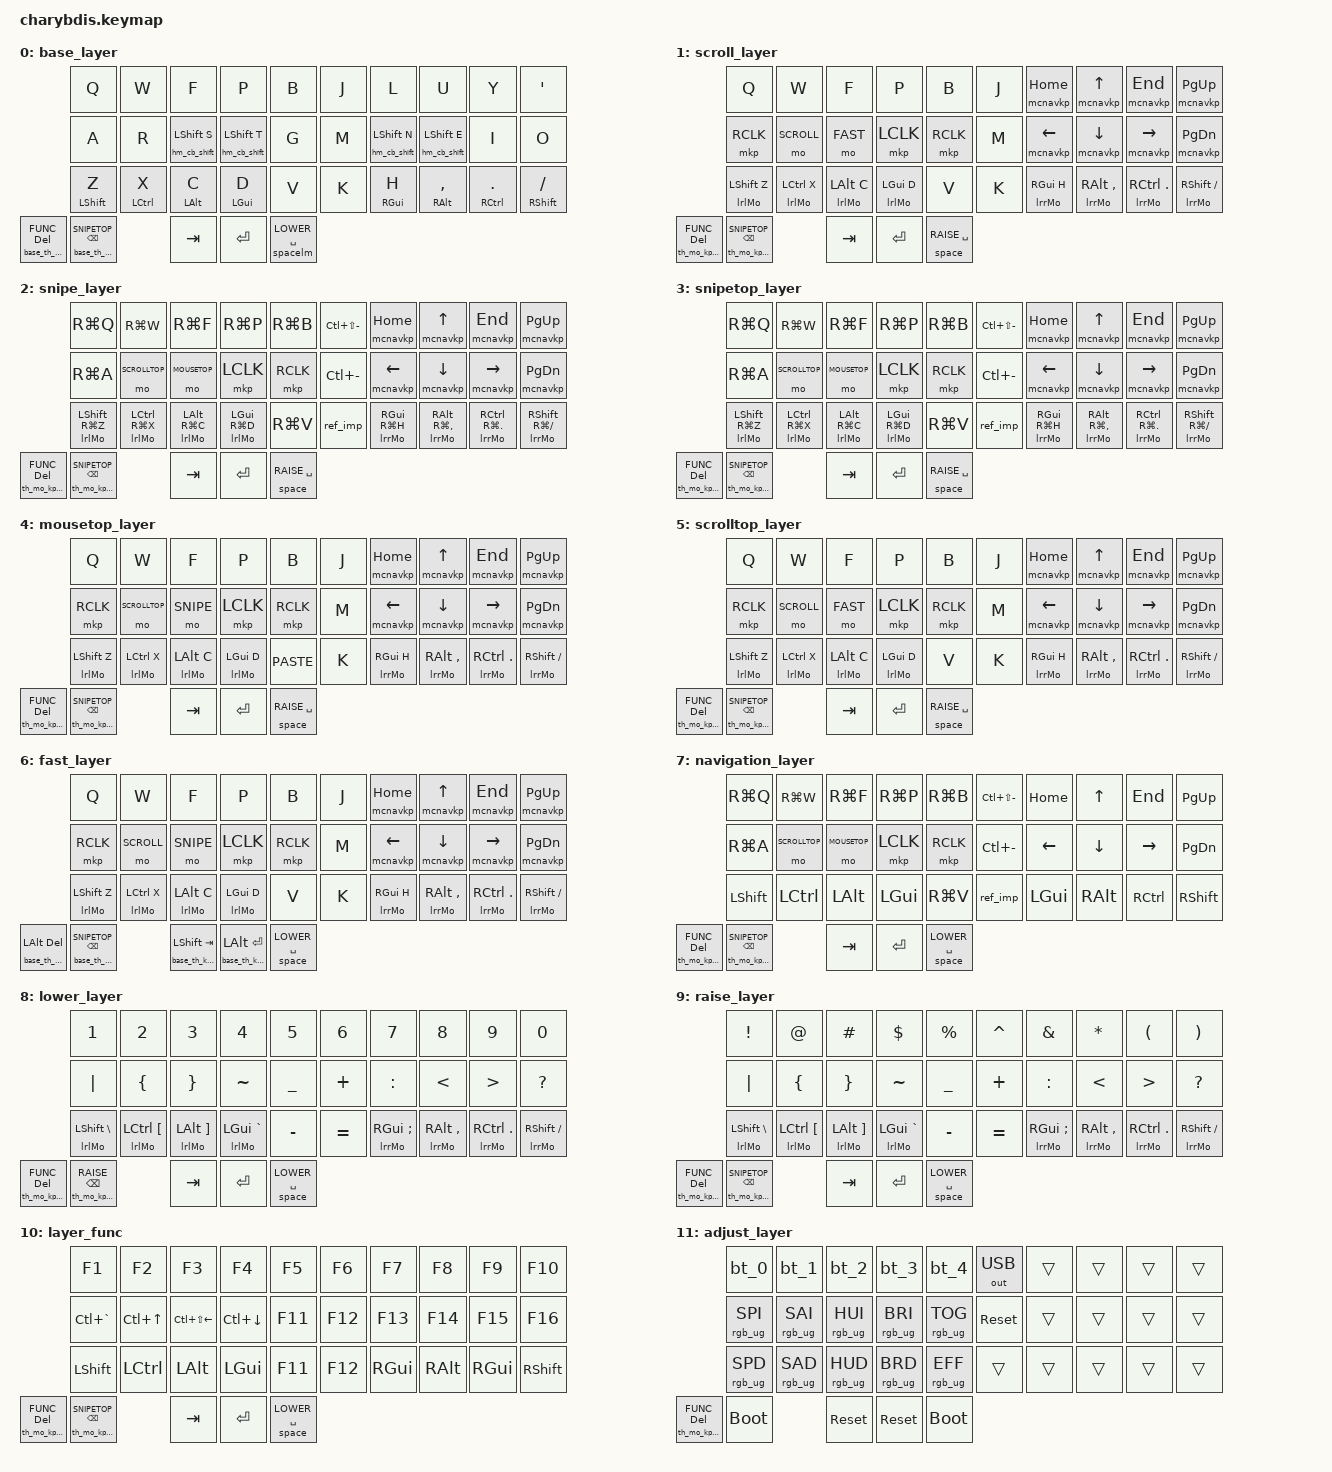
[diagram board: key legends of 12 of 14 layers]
/*
cd /Users/haroldhernandez/Charybdis/zmk-config-charybdis_nano

source ~/zephyrproject/.venv/bin/activate


//To install local zmk
# Tell west the config directory included in this repo
west init -l config
west update                # fetch Zephyr, ZMK, HALs
west zephyr-export         # sets Zephyr CMake package files in venv


west build -p \
  -s zmk/app -b nice_nano_v2 -d build/right \
  -S zmk-usb-logging \
  -S studio-rpc-usb-uart \
  -- \
  -DZMK_CONFIG="${PWD}/config" \
  -DOVERLAY_CONFIG=${PWD}/config/debug.conf \
  -DSHIELD=charybdis_right



west build -p \
  -s zmk/app -b nice_nano_v2 -d build/left \
  -S zmk-usb-logging \
  -- \
  -DZMK_CONFIG="${PWD}/config" \
  -DOVERLAY_CONFIG=${PWD}/config/debug.conf \
  -DSHIELD=charybdis_left

#To check the numbers:

   ls /dev/tty.usbmodem*   # data-terminal devices
   ls /dev/cu.usbmodem*    # call-up devices (identical, no HW flow-ctrl)

#and run to actuvate debug 
   sudo tio /dev/tty.usbmodem1101
   
-------------------------------------------------

west build -p \
  -s zmk/app -b nice_nano_v2 -d build/right \
  -- \
  -DZMK_CONFIG="${PWD}/config" \
  -DOVERLAY_CONFIG=${PWD}/config/debug.conf \
  -DSHIELD=charybdis_right



west build -p \
  -s zmk/app -b nice_nano_v2 -d build/left \
  -- \
  -DZMK_CONFIG="${PWD}/config" \
  -DOVERLAY_CONFIG=${PWD}/config/debug.conf \
  -DSHIELD=charybdis_left



  1. First boot — plug in USB, open a serial terminal:                                                           
  ls /dev/tty.usbmodem*                                                                                        
  screen /dev/tty.usbmodem* 115200                                                                               
  1. Confirm trackball works, note log output (should see PMW3610 initialized)                                   
  2. Power cycle — unplug USB, unplug battery, wait 5 seconds, plug battery back in, then plug USB back in       
  3. Second boot — open serial terminal again (the device name may change), check if PMW3610 initialized appears 
  or if you see errors/retries 


//ONLY RIGHT
west build -p \
  -s zmk/app -b nice_nano_v2 -d build/right \
  -S zmk-usb-logging \
  -- \
  -DZMK_CONFIG="${PWD}/config" \
  -DOVERLAY_CONFIG=${PWD}/config/debug.conf \
  -DSHIELD=charybdis_right


  west build -p \
  -s zmk/app -b nice_nano_v2 -d build/right \
  -S zmk-usb-logging \
  -- \
  -DZMK_CONFIG="${PWD}/config" \
  -DSHIELD=charybdis_right



  
west build -p \
  -s zmk/app -b nice_nano_v2 -d build/left \
  -- \
  -DZMK_CONFIG="${PWD}/config" \
  -DSHIELD=charybdis_left

west build -p \
  -s zmk/app -b nice_nano_v2 -d build/right \
  -- \
  -DZMK_CONFIG="${PWD}/config" \
  -DSHIELD=charybdis_right

*/

// ZMK_POINTING_DEFAULT_MOVE_VAL and ZMK_POINTING_DEFAULT_SCRL_VAL
// are defined in mouse.dtsi (included below)

/* On demand includes */

#include <behaviors/mouse_keys.dtsi>
#include <dt-bindings/zmk/mouse.h>
#include <behaviors.dtsi>
#include <behaviors/rgb_underglow.dtsi>
#include <dt-bindings/zmk/bt.h>
#include <dt-bindings/zmk/keys.h>
#include <dt-bindings/zmk/rgb.h>
#include <dt-bindings/zmk/outputs.h>
#include <dt-bindings/zmk/pointing.h>
//#include <input/processors.dtsi>


//     0  1  2  3  4         5  6  7  8  9
//    10 11 12 13 14        15 16 17 18 19
//    20 21 22 23 24        25 26 27 28 29 
//    30 31 32 33 34 35  36 37          38

//     0  1  2  3  4     5  6  7  8  9
//    10 11 12 13 14    15 16 17 18 19
//20  21 22 23 24 25    26 27 28 29 30  31
//        32 33 34         35 36 37


&lt {
    tapping-term-ms = <240>;
    flavor = "balanced";
    quick-tap-ms = <150>;
};

&mt {
    tapping-term-ms = <200>;
    flavor = "tap-preferred";
    quick-tap-ms = <150>;
};

&sl {
    release-after-ms = <4000>;
};

&caps_word { continue-list = <UNDERSCORE MINUS BACKSPACE>; };
#include "mouse.dtsi"

/ {
    chosen { zmk,matrix_transform = &five_column_transform; };
};

/ {

    #include "macros/macros_general.dtsi"
    #include "behaviors/behaviors_general.dtsi"
    #include "combos/combos_general.dtsi"

    keymap {
        compatible = "zmk,keymap";
        base_layer {
            bindings = <
                               &kp Q                &kp W               &kp F                      &kp P                     &kp B                     &kp J    &kp L                     &kp U                      &kp Y                &kp SQT
                               &kp A                &kp R               &hm_cb_shift LSHFT S       &hm_cb_shift LSHFT T      &kp G                     &kp M    &hm_cb_shift LSHFT N      &hm_cb_shift LSHFT E       &kp I                &kp O
                               &hml_hr LSHFT Z      &hml_hr LCTRL X     &hml_hr LALT C             &hml_hr LGUI D            &kp V                     &kp K    &hmr_hr RGUI H            &hmr_hr RALT COMMA         &hmr_hr RCTRL DOT    &hmr_hr RSHFT SLASH        
 &base_th_mo_kp_hp FUNC DEL  &base_th_mo_kp_hp SNIPETOP BACKSPACE  &kp TAB                 &kp ENTER  &spacelm LOWER SPACE  
            >;
        };

         scroll_layer {
            bindings = <
&kp Q                      &kp W                    &kp F                &kp P                 &kp B                                 &kp J           &mcnavkp HOME              &mcnavkp UP                    &mcnavkp END                    &mcnavkp PG_UP
&mkp RCLK                  &mo SCROLL               &mo FAST             &mkp LCLK             &mkp RCLK                             &kp M           &mcnavkp LEFT              &mcnavkp DOWN                  &mcnavkp RIGHT                  &mcnavkp PG_DN
&lrlMo LSHFT Z             &lrlMo LCTRL X           &lrlMo LALT C        &lrlMo LGUI D         &kp V                                 &kp K           &lrrMo RGUI H              &lrrMo RALT COMMA              &lrrMo RCTRL DOT                &lrrMo RSHFT SLASH 
//&kp DEL  &kp BACKSPACE  &kp TAB                  &kp ENTER   &kp SPACE   
  &th_mo_kp_hp FUNC DEL  &th_mo_kp_hp SNIPETOP BACKSPACE  &kp TAB                  &kp ENTER   &space RAISE SPACE   
            >;
        };

        snipe_layer {
            bindings = <
&kp RG(Q)                  &kp RG(W)                   &kp RG(F)             &kp RG(P)             &kp RG(B)                             &kp LC(LS(MINUS))           &mcnavkp HOME              &mcnavkp UP                    &mcnavkp END                    &mcnavkp PG_UP
&kp RG(A)                  &mo SCROLLTOP               &mo MOUSETOP          &mkp LCLK             &mkp RCLK                             &kp LC(MINUS)               &mcnavkp LEFT              &mcnavkp DOWN                  &mcnavkp RIGHT                  &mcnavkp PG_DN
&lrlMo LSHFT RG(Z)        &lrlMo LCTRL RG(X)         &lrlMo LALT RG(C)    &lrlMo LGUI RG(D)    &kp RG(V)                             &ref_imp                    &lrrMo RGUI RG(H)          &lrrMo RALT RG(COMMA)          &lrrMo RCTRL RG(DOT)            &lrrMo RSHFT RG(SLASH) 
//&kp DEL  &kp BACKSPACE  &kp TAB                  &kp ENTER   &kp SPACE   
  &th_mo_kp_hp FUNC DEL  &th_mo_kp_hp SNIPETOP BACKSPACE  &kp TAB                   &kp ENTER   &space RAISE SPACE   
            >;
        };

        snipetop_layer {
            bindings = <
&kp RG(Q)                  &kp RG(W)                   &kp RG(F)             &kp RG(P)             &kp RG(B)                             &kp LC(LS(MINUS))           &mcnavkp HOME              &mcnavkp UP                    &mcnavkp END                    &mcnavkp PG_UP
&kp RG(A)                  &mo SCROLLTOP               &mo MOUSETOP          &mkp LCLK             &mkp RCLK                             &kp LC(MINUS)               &mcnavkp LEFT              &mcnavkp DOWN                  &mcnavkp RIGHT                  &mcnavkp PG_DN
&lrlMo LSHFT RG(Z)        &lrlMo LCTRL RG(X)         &lrlMo LALT RG(C)    &lrlMo LGUI RG(D)    &kp RG(V)                             &ref_imp                    &lrrMo RGUI RG(H)          &lrrMo RALT RG(COMMA)          &lrrMo RCTRL RG(DOT)            &lrrMo RSHFT RG(SLASH) 
//&kp DEL  &kp BACKSPACE  &kp TAB                  &kp ENTER   &kp SPACE   
  &th_mo_kp_hp FUNC DEL  &th_mo_kp_hp SNIPETOP BACKSPACE  &kp TAB                   &kp ENTER   &space RAISE SPACE   
            >;
        };

        mousetop_layer {
            bindings = <
&kp Q                      &kp W                    &kp F                 &kp P                 &kp B                                   &kp J           &mcnavkp HOME              &mcnavkp UP                    &mcnavkp END                    &mcnavkp PG_UP
&mkp RCLK                  &mo SCROLLTOP            &mo SNIPE             &mkp LCLK             &mkp RCLK                               &kp M           &mcnavkp LEFT              &mcnavkp DOWN                  &mcnavkp RIGHT                  &mcnavkp PG_DN
&lrlMo LSHFT Z            &lrlMo LCTRL X          &lrlMo LALT C        &lrlMo LGUI D        &kp K_PASTE                             &kp K           &lrrMo RGUI H              &lrrMo RALT COMMA              &lrrMo RCTRL DOT                &lrrMo RSHFT SLASH 
//&kp DEL  &kp BACKSPACE  &kp TAB                  &kp ENTER   &kp SPACE   
 &th_mo_kp_hp FUNC DEL  &th_mo_kp_hp SNIPETOP BACKSPACE  &kp TAB                         &kp ENTER   &space RAISE SPACE   
            >;
        };

        scrolltop_layer {
            bindings = <
&kp Q                      &kp W                    &kp F                &kp P                 &kp B                                 &kp J               &mcnavkp HOME              &mcnavkp UP                    &mcnavkp END                    &mcnavkp PG_UP
&mkp RCLK                  &mo SCROLL               &mo FAST             &mkp LCLK             &mkp RCLK                             &kp M               &mcnavkp LEFT              &mcnavkp DOWN                  &mcnavkp RIGHT                  &mcnavkp PG_DN
&lrlMo LSHFT Z            &lrlMo LCTRL X          &lrlMo LALT C       &lrlMo LGUI D        &kp V                                 &kp K               &lrrMo RGUI H              &lrrMo RALT COMMA              &lrrMo RCTRL DOT                &lrrMo RSHFT SLASH 
//&kp DEL  &kp BACKSPACE  &kp TAB                  &kp ENTER   &kp SPACE   
 &th_mo_kp_hp FUNC DEL  &th_mo_kp_hp SNIPETOP BACKSPACE  &kp TAB                   &kp ENTER   &space RAISE SPACE   
            >;
        };

    fast_layer {
        bindings = <
&kp Q                      &kp W                    &kp F                  &kp P                  &kp B                                 &kp J               &mcnavkp HOME              &mcnavkp UP                    &mcnavkp END                    &mcnavkp PG_UP
&mkp RCLK                  &mo SCROLL               &mo SNIPE              &mkp LCLK              &mkp RCLK                             &kp M               &mcnavkp LEFT              &mcnavkp DOWN                  &mcnavkp RIGHT                  &mcnavkp PG_DN
&lrlMo LSHFT Z             &lrlMo LCTRL X           &lrlMo LALT C          &lrlMo LGUI D          &kp V                                 &kp K               &lrrMo RGUI H              &lrrMo RALT COMMA              &lrrMo RCTRL DOT                &lrrMo RSHFT SLASH 
 &base_th_mo_kp_hp LALT DEL  &base_th_mo_kp_hp SNIPETOP BACKSPACE  &base_th_kp_kp_hp LSHFT TAB                    &base_th_kp_kp_hp LALT ENTER  &space LOWER SPACE  
        >;
    };
    
    navigation_layer {
            bindings = <
&kp RG(Q)                  &kp RG(W)                   &kp RG(F)             &kp RG(P)             &kp RG(B)                             &kp LC(LS(MINUS))           &kp HOME                   &kp UP                         &kp END                         &kp PG_UP
&kp RG(A)                  &mo SCROLLTOP               &mo MOUSETOP          &mkp LCLK             &mkp RCLK                             &kp LC(MINUS)               &kp LEFT                   &kp DOWN                       &kp RIGHT                       &kp PG_DN
&kp LSHFT                  &kp LCTRL                   &kp LALT              &kp LGUI              &kp RG(V)                             &ref_imp                    &kp LGUI                   &kp RALT                       &kp RCTRL                       &kp RSHFT  
//&kp DEL  &kp BACKSPACE  &kp TAB                  &kp ENTER   &kp SPACE   
  &th_mo_kp_hp FUNC DEL  &th_mo_kp_hp SNIPETOP BACKSPACE  &kp TAB                   &kp ENTER   &space LOWER SPACE   
            >;
        };

        lower_layer {
            bindings = <
                  &kp N1                         &kp N2                        &kp N3                        &kp N4              &kp N5                                    &kp N6             &kp N7                    &kp N8                   &kp N9                 &kp N0
                  &kp PIPE                       &kp LBRC                      &kp RBRC                      &kp TILDE           &kp UNDER                                 &kp PLUS           &kp COLON                 &kp LT                   &kp GT                 &kp QUESTION
                  &lrlMo LSHFT BSLH              &lrlMo LCTRL LBKT             &lrlMo LALT RBKT              &lrlMo LGUI GRAVE   &kp MINUS                                 &kp EQUAL          &lrrMo RGUI SEMI          &lrrMo RALT COMMA        &lrrMo RCTRL DOT       &lrrMo RSHFT SLASH 
//&kp DEL  &kp BACKSPACE  &kp TAB                  &kp ENTER   &kp SPACE   
  &th_mo_kp_hp FUNC DEL  &th_mo_kp_hp RAISE BACKSPACE  &kp TAB                   &kp ENTER   &space LOWER SPACE   
            >;
        };

        raise_layer {
            bindings = <
                  &kp EXCL                   &kp AT                      &kp HASH                         &kp DLLR                          &kp PRCNT                             &kp CARET           &kp AMPS                   &kp STAR                  &kp LPAR                  &kp RPAR
                  &kp PIPE                   &kp LBRC                    &kp RBRC                         &kp TILDE                         &kp UNDER                             &kp PLUS            &kp COLON                  &kp LT                   &kp GT                     &kp QUESTION
                  &lrlMo LSHFT BSLH          &lrlMo LCTRL LBKT           &lrlMo LALT RBKT                 &lrlMo LGUI GRAVE                 &kp MINUS                             &kp EQUAL           &lrrMo RGUI SEMI           &lrrMo RALT COMMA         &lrrMo RCTRL DOT          &lrrMo RSHFT SLASH              
//&kp DEL  &kp BACKSPACE  &kp TAB                  &kp ENTER   &kp SPACE   
 &th_mo_kp_hp FUNC DEL  &th_mo_kp_hp SNIPETOP BACKSPACE  &kp TAB                   &kp ENTER   &space LOWER SPACE  
            >;
        };

        layer_func {
            bindings = <
        &kp F1          &kp F2         &kp F3                &kp F4           &kp F5                              &kp F6             &kp F7              &kp F8            &kp F9            &kp F10
        &kp LC(GRAVE)   &kp LC(UP)     &kp LC(LS(LEFT))      &kp LC(DOWN)     &kp F11                             &kp F12            &kp F13             &kp F14           &kp F15           &kp F16 
        &kp LSHFT       &kp LCTRL      &kp LALT              &kp LGUI         &kp F11                             &kp F12            &kp RGUI            &kp RALT          &kp RGUI          &kp RSHFT      
//&kp DEL  &kp BACKSPACE  &kp TAB                  &kp ENTER   &kp SPACE   
  &th_mo_kp_hp FUNC DEL  &th_mo_kp_hp SNIPETOP BACKSPACE  &kp TAB                   &kp ENTER   &space LOWER SPACE  
            >;
        };

        adjust_layer {
            bindings = <
            &bt_0               &bt_1               &bt_2               &bt_3               &bt_4                                       &out OUT_USB            &trans                    &trans                    &trans           &trans
            &rgb_ug RGB_SPI     &rgb_ug RGB_SAI     &rgb_ug RGB_HUI     &rgb_ug RGB_BRI     &rgb_ug RGB_TOG                             &sys_reset              &trans                    &trans                    &trans           &trans
            &rgb_ug RGB_SPD     &rgb_ug RGB_SAD     &rgb_ug RGB_HUD     &rgb_ug RGB_BRD     &rgb_ug RGB_EFF                             &trans                  &trans                    &trans                    &trans           &trans
  &th_mo_kp_hp FUNC DEL   &bootloader   &sys_reset                                                &sys_reset   &bootloader 
            >;
        };

        layer_numbers {
            bindings = <
                  &kp EXCL                   &kp AT                      &kp HASH                         &kp DLLR                          &kp PRCNT                             &kp DOT            &kp N7                    &kp N8                   &kp N9           &kp N0 
                  &kp PIPE                   &kp LBRC                    &kp RBRC                         &kp TILDE                         &kp COMMA                             &kp PLUS           &kp N4                    &kp N5                   &kp N6           &kp STAR
                  &lrlMo LSHFT BSLH          &lrlMo LCTRL LBKT           &lrlMo LALT RBKT                 &lrlMo LGUI GRAVE                 &kp MINUS                             &kp EQUAL          &kp N1                    &kp N2                   &kp N3           &kp SLASH        
//&kp DEL  &kp BACKSPACE  &kp TAB                  &kp ENTER   &kp SPACE   
  &th_mo_kp_hp FUNC DEL  &th_mo_kp_hp SNIPETOP BACKSPACE  &kp TAB                   &kp ENTER   &space LOWER SPACE  
            >;
        };

        layer_system {
            bindings = <
&kp C_BRI_DN           &kp C_BRI_UP               &none                         &none              &none                             &kp C_VOL_UP     &kp C_PREV         &kp C_PP           &kp C_NEXT      &mc_lock_screen
&bt_0                  &bt_1                      &bt_2                         &bt_3              &out OUT_USB                      &kp C_VOL_DN     &bt_0              &bt_1              &bt_2           &out OUT_USB
&kp LSHFT              &kp LCTRL                  &kp LALT                      &kp LGUI           &none                             &kp C_MUTE       &kp RGUI           &kp RALT           &kp RCTRL       &kp RSHFT
//&kp DEL  &kp BACKSPACE  &kp TAB                  &kp ENTER   &kp SPACE   
  &th_mo_kp_hp FUNC DEL  &th_mo_kp_hp SNIPETOP BACKSPACE  &kp TAB                   &kp ENTER   &space LOWER SPACE  
            >;
        };


    };

};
